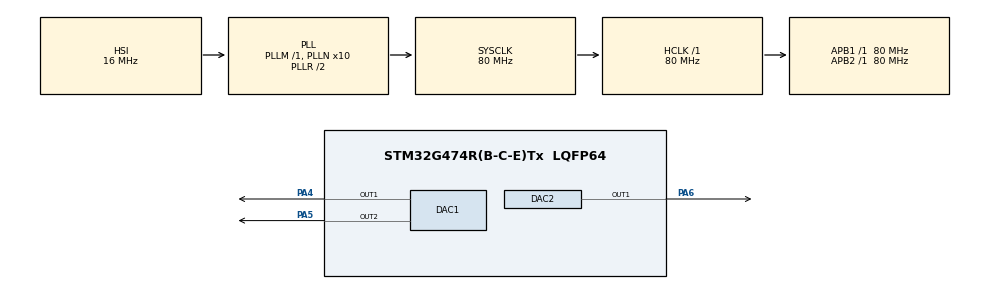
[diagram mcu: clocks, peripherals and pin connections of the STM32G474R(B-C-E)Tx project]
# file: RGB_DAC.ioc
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DAC1.DAC_Channel-DAC_OUT2=DAC_CHANNEL_2
Mcu.Family=STM32G4
Mcu.Name=STM32G474R(B-C-E)Tx
Mcu.Package=LQFP64
NVIC.PriorityGroup=NVIC_PRIORITYGROUP_4
NVIC.TIM6_DAC_IRQn=true\:1\:0\:true\:false\:true\:true\:true\:true
PA13.Mode=Serial_Wire
PA13.Signal=SYS_JTMS-SWDIO
PA14.Mode=Serial_Wire
PA14.Signal=SYS_JTCK-SWCLK
PA4.Signal=COMP_DAC11_group
PA5.Signal=COMP_DAC12_group
PA6.Signal=COMP_DAC21_group
ProjectManager.HeapSize=0x200
ProjectManager.StackSize=0x400
ProjectManager.TargetToolchain=STM32CubeIDE
RCC.ADC12Freq_Value=80000000
RCC.ADC345Freq_Value=80000000
RCC.AHBFreq_Value=80000000
RCC.APB1Freq_Value=80000000
RCC.APB1TimFreq_Value=80000000
RCC.APB2Freq_Value=80000000
RCC.APB2TimFreq_Value=80000000
RCC.CortexFreq_Value=80000000
RCC.EXTERNAL_CLOCK_VALUE=12288000
RCC.HCLKFreq_Value=80000000
RCC.HSE_VALUE=8000000
RCC.HSI48_VALUE=48000000
RCC.HSI_VALUE=16000000
RCC.LSE_VALUE=32768
RCC.PLLN=10
RCC.SYSCLKFreq_VALUE=80000000
RCC.SYSCLKSource=RCC_SYSCLKSOURCE_PLLCLK
RCC.USBFreq_Value=80000000
RCC.VCOOutputFreq_Value=160000000
SH.COMP_DAC11_group.0=DAC1_OUT1,DAC_OUT1
SH.COMP_DAC12_group.0=DAC1_OUT2,DAC_OUT2
SH.COMP_DAC21_group.0=DAC2_OUT1,DAC_OUT1
TIM6.PeriodNoDither=1
TIM6.Prescaler=9769
VP_TIM6_VS_ClockSourceINT.Mode=Enable_Timer
board=custom

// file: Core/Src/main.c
/* USER CODE BEGIN Header */
/**
  ******************************************************************************
  * @file           : main.c
  * @brief          : Main program body
  ******************************************************************************
  * @attention
  *
  * Copyright (c) 2023 STMicroelectronics.
  * All rights reserved.
  *
  * This software is licensed under terms that can be found in the LICENSE file
  * in the root directory of this software component.
  * If no LICENSE file comes with this software, it is provided AS-IS.
  *
  ******************************************************************************
  */
/* USER CODE END Header */
#include "main.h"

/* USER CODE BEGIN Includes */
#include "math.h"
#include "stdbool.h"
/* USER CODE END Includes */

DAC_HandleTypeDef hdac1;
DAC_HandleTypeDef hdac2;

TIM_HandleTypeDef htim6;

void SystemClock_Config(void);
static void MX_GPIO_Init(void);
static void MX_DAC1_Init(void);
static void MX_DAC2_Init(void);
static void MX_TIM6_Init(void);

/* USER CODE BEGIN 0 */
uint32_t t=0;          		// time for u_sine
uint32_t old_t=0;      		// last time
uint32_t new_t=0;      		// actual time
uint32_t u_sine=0;     		// momentary value of sinusoidal voltage (from 0 to 4095)
int sawtooth_psc=0;    		// prescaler which divides the frequency of triangular wave for sawtooth wave
uint32_t u_sawtooth=0; 		// momentary value of sawtooth voltage (from 0 to 4095)
bool triangle_dir=0;   		// declares whether the triangular voltage should increase or decrease
uint32_t u_triangle=0;  	// momentary value of triangular voltage (from 0 to 4095)

uint32_t sine(t){                                    		// function to calculate the sine value for each millisecond
    u_sine=(sin(t*((2*M_PI)/2000))+1)*(((0xFFF)+1)/2); 		// calculate u_sine(t)
    return u_sine;                                    		// return u_sine(t)
}

void sawtooth(){               	 // function to calculate u_sawtooth
    u_sawtooth++;                // increase the voltage value in the range from 0 to 4095
    if (u_sawtooth>=4095){       // check if the value of u_sawtooth is at its maximum
        u_sawtooth=0;            // perform a sudden "drop" to 0V and start increasing the voltage again
    }
}

void triangle(){                	// function to calculate u_triangle
    if (triangle_dir==1){        	// check whether the voltage should increase or decrease
        u_triangle++;            	// function should increase, increase the voltage value in the range from 0 to 4095
        if (u_triangle>=4095){   	// check if the value of u_triangle is at its maximum
            triangle_dir=0;      	// change from increasing voltage to decreasing voltage
        }
    }
    else{                        	// function should decrease
        u_triangle--;            	// decrease the voltage value in the range from 0 to 4095
        if (u_triangle<=0){        	// check if the value of u_triangle is at its minimum
            triangle_dir=1;        	// change from decreasing voltage to increasing voltage
        }
    }
}

void HAL_TIM_PeriodElapsedCallback(TIM_HandleTypeDef *htim){  	// function handling interrupts from timers
    if (htim==&htim6){              // check if the interrupt comes from TIM6
        triangle();                 // call the triangle() function
        sawtooth_psc++;             // increase the frequency divider value for the sawtooth wave
        if(sawtooth_psc>=2){        // check if the divider value has reached the appropriate value
            sawtooth();            	// call the sawtooth() function
            sawtooth_psc=0;         // set the frequency divider back to 0 so that the sawtooth and triangle waves have the same period
        }

    }
}
/* USER CODE END 0 */

int main(void)
{

  /* MCU Configuration--------------------------------------------------------*/

  /* Reset of all peripherals, Initializes the Flash interface and the Systick. */
  HAL_Init();

  /* Configure the system clock */
  SystemClock_Config();

  /* Initialize all configured peripherals */
  MX_GPIO_Init();
  MX_DAC1_Init();
  MX_DAC2_Init();
  MX_TIM6_Init();

  /* Infinite loop */
  /* USER CODE BEGIN WHILE */
  while (1)
  {
      new_t = HAL_GetTick();                // Get the current time elapsed since the uC started
      if (old_t != new_t)                   // Check if the previous time value is different from the current one
      {
          old_t = new_t;                    // Assign the previous time value to the current one
          t = new_t;                        // Assign the variable t the current time value
          sine(t);                          // Call the sine() function
      }

      HAL_DAC_SetValue(&hdac1, DAC_CHANNEL_1, DAC_ALIGN_12B_R, u_sine);     	// Set the value of u_sine on channel 1 of DAC1 (Red LED)
      HAL_DAC_SetValue(&hdac1, DAC_CHANNEL_2, DAC_ALIGN_12B_R, u_sawtooth); 	// Set the value of u_sawtooth on channel 2 of DAC1 (Green LED)
      HAL_DAC_SetValue(&hdac2, DAC_CHANNEL_1, DAC_ALIGN_12B_R, u_triangle); 	// Set the value of u_sine on channel 1 of DAC2 (Blue LED)
    /* USER CODE END WHILE */

  }
}

void SystemClock_Config(void)
{
  RCC_OscInitTypeDef RCC_OscInitStruct = {0};
  RCC_ClkInitTypeDef RCC_ClkInitStruct = {0};

  /** Configure the main internal regulator output voltage
  */
  HAL_PWREx_ControlVoltageScaling(PWR_REGULATOR_VOLTAGE_SCALE1);

  /** Initializes the RCC Oscillators according to the specified parameters
  * in the RCC_OscInitTypeDef structure.
  */
  RCC_OscInitStruct.OscillatorType = RCC_OSCILLATORTYPE_HSI;
  RCC_OscInitStruct.HSIState = RCC_HSI_ON;
  RCC_OscInitStruct.HSICalibrationValue = RCC_HSICALIBRATION_DEFAULT;
  RCC_OscInitStruct.PLL.PLLState = RCC_PLL_ON;
  RCC_OscInitStruct.PLL.PLLSource = RCC_PLLSOURCE_HSI;
  RCC_OscInitStruct.PLL.PLLM = RCC_PLLM_DIV1;
  RCC_OscInitStruct.PLL.PLLN = 10;
  RCC_OscInitStruct.PLL.PLLP = RCC_PLLP_DIV2;
  RCC_OscInitStruct.PLL.PLLQ = RCC_PLLQ_DIV2;
  RCC_OscInitStruct.PLL.PLLR = RCC_PLLR_DIV2;
  if (HAL_RCC_OscConfig(&RCC_OscInitStruct) != HAL_OK)
  {
    Error_Handler();
  }

  /** Initializes the CPU, AHB and APB buses clocks
  */
  RCC_ClkInitStruct.ClockType = RCC_CLOCKTYPE_HCLK|RCC_CLOCKTYPE_SYSCLK
                              |RCC_CLOCKTYPE_PCLK1|RCC_CLOCKTYPE_PCLK2;
  RCC_ClkInitStruct.SYSCLKSource = RCC_SYSCLKSOURCE_PLLCLK;
  RCC_ClkInitStruct.AHBCLKDivider = RCC_SYSCLK_DIV1;
  RCC_ClkInitStruct.APB1CLKDivider = RCC_HCLK_DIV1;
  RCC_ClkInitStruct.APB2CLKDivider = RCC_HCLK_DIV1;

  if (HAL_RCC_ClockConfig(&RCC_ClkInitStruct, FLASH_LATENCY_2) != HAL_OK)
  {
    Error_Handler();
  }
}

static void MX_DAC1_Init(void)
{

  DAC_ChannelConfTypeDef sConfig = {0};

  /** DAC Initialization
  */
  hdac1.Instance = DAC1;
  if (HAL_DAC_Init(&hdac1) != HAL_OK)
  {
    Error_Handler();
  }

  /** DAC channel OUT1 config
  */
  sConfig.DAC_HighFrequency = DAC_HIGH_FREQUENCY_INTERFACE_MODE_AUTOMATIC;
  sConfig.DAC_DMADoubleDataMode = DISABLE;
  sConfig.DAC_SignedFormat = DISABLE;
  sConfig.DAC_SampleAndHold = DAC_SAMPLEANDHOLD_DISABLE;
  sConfig.DAC_Trigger = DAC_TRIGGER_NONE;
  sConfig.DAC_Trigger2 = DAC_TRIGGER_NONE;
  sConfig.DAC_OutputBuffer = DAC_OUTPUTBUFFER_ENABLE;
  sConfig.DAC_ConnectOnChipPeripheral = DAC_CHIPCONNECT_EXTERNAL;
  sConfig.DAC_UserTrimming = DAC_TRIMMING_FACTORY;
  if (HAL_DAC_ConfigChannel(&hdac1, &sConfig, DAC_CHANNEL_1) != HAL_OK)
  {
    Error_Handler();
  }

  /** DAC channel OUT2 config
  */
  if (HAL_DAC_ConfigChannel(&hdac1, &sConfig, DAC_CHANNEL_2) != HAL_OK)
  {
    Error_Handler();
  }

}

static void MX_DAC2_Init(void)
{

  DAC_ChannelConfTypeDef sConfig = {0};

  /** DAC Initialization
  */
  hdac2.Instance = DAC2;
  if (HAL_DAC_Init(&hdac2) != HAL_OK)
  {
    Error_Handler();
  }

  /** DAC channel OUT1 config
  */
  sConfig.DAC_HighFrequency = DAC_HIGH_FREQUENCY_INTERFACE_MODE_AUTOMATIC;
  sConfig.DAC_DMADoubleDataMode = DISABLE;
  sConfig.DAC_SignedFormat = DISABLE;
  sConfig.DAC_SampleAndHold = DAC_SAMPLEANDHOLD_DISABLE;
  sConfig.DAC_Trigger = DAC_TRIGGER_NONE;
  sConfig.DAC_Trigger2 = DAC_TRIGGER_NONE;
  sConfig.DAC_OutputBuffer = DAC_OUTPUTBUFFER_ENABLE;
  sConfig.DAC_ConnectOnChipPeripheral = DAC_CHIPCONNECT_EXTERNAL;
  sConfig.DAC_UserTrimming = DAC_TRIMMING_FACTORY;
  if (HAL_DAC_ConfigChannel(&hdac2, &sConfig, DAC_CHANNEL_1) != HAL_OK)
  {
    Error_Handler();
  }

}

static void MX_TIM6_Init(void)
{

  TIM_MasterConfigTypeDef sMasterConfig = {0};

  htim6.Instance = TIM6;
  htim6.Init.Prescaler = 9769;
  htim6.Init.CounterMode = TIM_COUNTERMODE_UP;
  htim6.Init.Period = 1;
  htim6.Init.AutoReloadPreload = TIM_AUTORELOAD_PRELOAD_DISABLE;
  if (HAL_TIM_Base_Init(&htim6) != HAL_OK)
  {
    Error_Handler();
  }
  sMasterConfig.MasterOutputTrigger = TIM_TRGO_RESET;
  sMasterConfig.MasterSlaveMode = TIM_MASTERSLAVEMODE_DISABLE;
  if (HAL_TIMEx_MasterConfigSynchronization(&htim6, &sMasterConfig) != HAL_OK)
  {
    Error_Handler();
  }

}

static void MX_GPIO_Init(void)
{

  /* GPIO Ports Clock Enable */
  __HAL_RCC_GPIOA_CLK_ENABLE();

}

void Error_Handler(void)
{
  __disable_irq();
  while (1)
  {
  }
}
